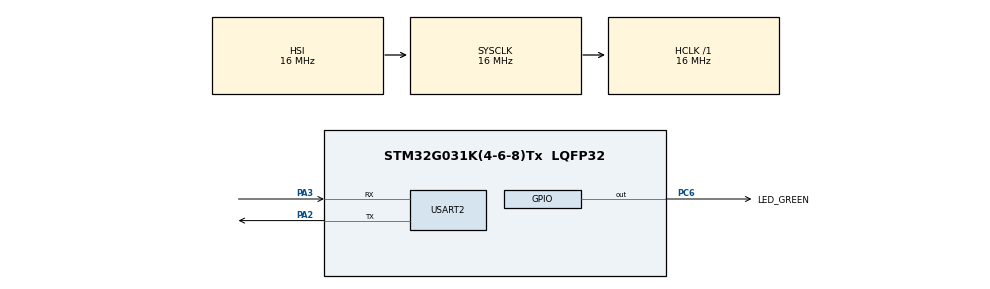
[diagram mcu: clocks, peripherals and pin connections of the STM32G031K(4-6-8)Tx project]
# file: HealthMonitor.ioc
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ADC1.Channel-0\#ChannelRegularConversion=ADC_CHANNEL_TEMPSENSOR
ADC1.Channel-1\#ChannelRegularConversion=ADC_CHANNEL_VREFINT
ADC1.ContinuousConvMode=ENABLE
ADC1.DMAContinuousRequests=ENABLE
ADC1.NbrOfConversion=2
ADC1.NbrOfConversionFlag=1
ADC1.Rank-1\#ChannelRegularConversion=2
ADC1.SamplingTime-1\#ChannelRegularConversion=ADC_SAMPLINGTIME_COMMON_1
ADC1.SamplingTimeCommon1=ADC_SAMPLETIME_160CYCLES_5
ADC1.SelectedChannel=ADC_CHANNEL_TEMPSENSOR|ADC_CHANNEL_VREFINT
ADC1.master=1
Dma.ADC1.0.Direction=DMA_PERIPH_TO_MEMORY
Dma.ADC1.0.EventEnable=DISABLE
Dma.ADC1.0.Instance=DMA1_Channel1
Dma.ADC1.0.MemDataAlignment=DMA_MDATAALIGN_HALFWORD
Dma.ADC1.0.MemInc=DMA_MINC_ENABLE
Dma.ADC1.0.Mode=DMA_CIRCULAR
Dma.ADC1.0.PeriphDataAlignment=DMA_PDATAALIGN_HALFWORD
Dma.ADC1.0.PeriphInc=DMA_PINC_DISABLE
Dma.ADC1.0.Polarity=HAL_DMAMUX_REQ_GEN_RISING
Dma.ADC1.0.Priority=DMA_PRIORITY_LOW
Dma.ADC1.0.RequestNumber=1
Dma.ADC1.0.SignalID=NONE
Dma.ADC1.0.SyncEnable=DISABLE
Dma.ADC1.0.SyncPolarity=HAL_DMAMUX_SYNC_NO_EVENT
Dma.ADC1.0.SyncRequestNumber=1
Dma.ADC1.0.SyncSignalID=NONE
Dma.Request0=ADC1
Mcu.Family=STM32G0
Mcu.Name=STM32G031K(4-6-8)Tx
Mcu.Package=LQFP32
NVIC.DMA1_Channel1_IRQn=true\:0\:0\:false\:false\:true\:false\:true\:true
PA2.Mode=Asynchronous
PA2.Signal=USART2_TX
PA3.Mode=Asynchronous
PA3.Signal=USART2_RX
PC6.GPIO_Label=LED_GREEN
PC6.Signal=GPIO_Output
ProjectManager.HeapSize=0x200
ProjectManager.StackSize=0x400
ProjectManager.TargetToolchain=STM32CubeIDE
RCC.AHBFreq_Value=16000000
RCC.CortexFreq_Value=16000000
RCC.EXTERNAL_CLOCK_VALUE=12288000
RCC.HCLKFreq_Value=16000000
RCC.HSE_VALUE=8000000
RCC.HSI_VALUE=16000000
RCC.LSE_VALUE=32768
RCC.SYSCLKFreq_VALUE=16000000
RCC.VCOOutputFreq_Value=128000000
USART2.VirtualMode-Asynchronous=VM_ASYNC
VP_ADC1_TempSens_Input.Mode=IN-TempSens
VP_ADC1_Vref_Input.Mode=IN-Vrefint
board=NUCLEO-G031K8

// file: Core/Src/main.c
/* USER CODE BEGIN Header */
/**
 ******************************************************************************
 * @file           : main.c
 * @brief          : Main program body
 ******************************************************************************
 * @attention
 *
 * Copyright (c) 2026 STMicroelectronics.
 * All rights reserved.
 *
 * This software is licensed under terms that can be found in the LICENSE file
 * in the root directory of this software component.
 * If no LICENSE file comes with this software, it is provided AS-IS.
 *
 ******************************************************************************
 */
/* USER CODE END Header */
#include "main.h"

/* USER CODE BEGIN Includes */
#include <stdio.h>
#include <string.h>
/* USER CODE END Includes */

ADC_HandleTypeDef hadc1;
DMA_HandleTypeDef hdma_adc1;

UART_HandleTypeDef huart2;

/* USER CODE BEGIN PV */
// Buffer to hold raw data: [0]=Temp, [1]=Vref
uint16_t adc_buffer[2];
/* USER CODE END PV */

void SystemClock_Config(void);
static void MX_DMA_Init(void);
static void MX_GPIO_Init(void);
static void MX_ADC1_Init(void);
static void MX_USART2_UART_Init(void);

int main(void)
{

  /* MCU Configuration--------------------------------------------------------*/

  /* Reset of all peripherals, Initializes the Flash interface and the Systick. */
  HAL_Init();

  /* Configure the system clock */
  SystemClock_Config();

  /* Initialize all configured peripherals */
  MX_DMA_Init();
  MX_GPIO_Init();
  MX_ADC1_Init();
  MX_USART2_UART_Init();
  /* USER CODE BEGIN 2 */
	// Calibrate the ADC for better accuracy
	HAL_ADCEx_Calibration_Start(&hadc1);

	// Start the ADC in DMA mode
	// It will fill 'adc_buffer' and loop back to start automatically
	HAL_ADC_Start_DMA(&hadc1, (uint32_t*) adc_buffer, 2);
  /* USER CODE END 2 */

  /* Infinite loop */
  /* USER CODE BEGIN WHILE */
	char msg[64];

	// 1. Define the Factory Calibration Addresses (From Datasheet)
#define TS_CAL1_ADDR ((uint16_t*) ((uint32_t)0x1FFF75A8)) // Value at 30 degrees C
#define TS_CAL2_ADDR ((uint16_t*) ((uint32_t)0x1FFF75CA)) // Value at 130 degrees C
#ifndef VREFINT_CAL_ADDR
    #define VREFINT_CAL_ADDR   ((uint16_t*) ((uint32_t)0x1FFF75AA)) // 3.0V
#endif

	while (1) {
		// --- Step 1: Calculate Actual System Voltage (VDDA) ---
		// We use the Internal Reference (Vref) to find out the real supply voltage
		uint16_t vref_cal = *VREFINT_CAL_ADDR;
		uint16_t vref_data = adc_buffer[1];

		// Formula: VDDA = 3.0V * (VREF_CAL / VREF_DATA)
		// Result in millivolts (e.g., 3300 mV)
		uint32_t vdda_mv = (3000 * vref_cal) / vref_data;

		// --- Step 2: Calculate Temperature ---
		// We use the slope formula with the calibration points
		int32_t ts_cal1 = (int32_t) *TS_CAL1_ADDR;
		int32_t ts_cal2 = (int32_t) *TS_CAL2_ADDR;

		// Normalize the raw reading to 3.0V reference
		// (Raw * Actual_Voltage) / 3000mV
		int32_t ts_data_raw = (int32_t) adc_buffer[0];
		int32_t ts_data_corrected = (ts_data_raw * vdda_mv) / 3000;
		// Standard Linear Interpolation Formula for STM32
		int32_t temperature_c = ((110 * (ts_data_corrected - ts_cal1))
				/ (ts_cal2 - ts_cal1)) + 30;

		// --- Step 3: Print Results ---
		// CSV Format (Voltage,Temperature)
		sprintf(msg, "%lu,%ld\r\n", vdda_mv, temperature_c);
		//sprintf(msg, "Volt: %lu mV | Temp: %ld C\r\n", vdda_mv, temperature_c);
		HAL_UART_Transmit(&huart2, (uint8_t*) msg, strlen(msg), 100);

		HAL_Delay(1000);

		// --- Step 4: System Protection (The "Thermostat") ---
		// If we touch the chip and it warms up, trigger the alarm.
		if (temperature_c > 31) {
			// HOT! Turn on LED (PC6 for Nucleo-G031K8)
			HAL_GPIO_WritePin(GPIOC, GPIO_PIN_6, GPIO_PIN_SET);
			strcat(msg, " [ALARM: OVERHEATING]"); // Append warning to UART log
		} else {
			// Cool. Turn off LED.
			HAL_GPIO_WritePin(GPIOC, GPIO_PIN_6, GPIO_PIN_RESET);
		}

    /* USER CODE END WHILE */

	}
}

void SystemClock_Config(void)
{
  RCC_OscInitTypeDef RCC_OscInitStruct = {0};
  RCC_ClkInitTypeDef RCC_ClkInitStruct = {0};

  /** Configure the main internal regulator output voltage
  */
  HAL_PWREx_ControlVoltageScaling(PWR_REGULATOR_VOLTAGE_SCALE1);

  /** Initializes the RCC Oscillators according to the specified parameters
  * in the RCC_OscInitTypeDef structure.
  */
  RCC_OscInitStruct.OscillatorType = RCC_OSCILLATORTYPE_HSI;
  RCC_OscInitStruct.HSIState = RCC_HSI_ON;
  RCC_OscInitStruct.HSIDiv = RCC_HSI_DIV1;
  RCC_OscInitStruct.HSICalibrationValue = RCC_HSICALIBRATION_DEFAULT;
  RCC_OscInitStruct.PLL.PLLState = RCC_PLL_NONE;
  if (HAL_RCC_OscConfig(&RCC_OscInitStruct) != HAL_OK)
  {
    Error_Handler();
  }

  /** Initializes the CPU, AHB and APB buses clocks
  */
  RCC_ClkInitStruct.ClockType = RCC_CLOCKTYPE_HCLK|RCC_CLOCKTYPE_SYSCLK
                              |RCC_CLOCKTYPE_PCLK1;
  RCC_ClkInitStruct.SYSCLKSource = RCC_SYSCLKSOURCE_HSI;
  RCC_ClkInitStruct.AHBCLKDivider = RCC_SYSCLK_DIV1;
  RCC_ClkInitStruct.APB1CLKDivider = RCC_HCLK_DIV1;

  if (HAL_RCC_ClockConfig(&RCC_ClkInitStruct, FLASH_LATENCY_0) != HAL_OK)
  {
    Error_Handler();
  }
}

static void MX_ADC1_Init(void)
{

  ADC_ChannelConfTypeDef sConfig = {0};

  /** Configure the global features of the ADC (Clock, Resolution, Data Alignment and number of conversion)
  */
  hadc1.Instance = ADC1;
  hadc1.Init.ClockPrescaler = ADC_CLOCK_SYNC_PCLK_DIV2;
  hadc1.Init.Resolution = ADC_RESOLUTION_12B;
  hadc1.Init.DataAlign = ADC_DATAALIGN_RIGHT;
  hadc1.Init.ScanConvMode = ADC_SCAN_ENABLE;
  hadc1.Init.EOCSelection = ADC_EOC_SINGLE_CONV;
  hadc1.Init.LowPowerAutoWait = DISABLE;
  hadc1.Init.LowPowerAutoPowerOff = DISABLE;
  hadc1.Init.ContinuousConvMode = ENABLE;
  hadc1.Init.NbrOfConversion = 2;
  hadc1.Init.ExternalTrigConv = ADC_SOFTWARE_START;
  hadc1.Init.ExternalTrigConvEdge = ADC_EXTERNALTRIGCONVEDGE_NONE;
  hadc1.Init.DMAContinuousRequests = ENABLE;
  hadc1.Init.Overrun = ADC_OVR_DATA_PRESERVED;
  hadc1.Init.SamplingTimeCommon1 = ADC_SAMPLETIME_160CYCLES_5;
  hadc1.Init.SamplingTimeCommon2 = ADC_SAMPLETIME_1CYCLE_5;
  hadc1.Init.OversamplingMode = DISABLE;
  hadc1.Init.TriggerFrequencyMode = ADC_TRIGGER_FREQ_HIGH;
  if (HAL_ADC_Init(&hadc1) != HAL_OK)
  {
    Error_Handler();
  }

  /** Configure Regular Channel
  */
  sConfig.Channel = ADC_CHANNEL_TEMPSENSOR;
  sConfig.Rank = ADC_REGULAR_RANK_1;
  sConfig.SamplingTime = ADC_SAMPLINGTIME_COMMON_1;
  if (HAL_ADC_ConfigChannel(&hadc1, &sConfig) != HAL_OK)
  {
    Error_Handler();
  }

  /** Configure Regular Channel
  */
  sConfig.Channel = ADC_CHANNEL_VREFINT;
  sConfig.Rank = ADC_REGULAR_RANK_2;
  if (HAL_ADC_ConfigChannel(&hadc1, &sConfig) != HAL_OK)
  {
    Error_Handler();
  }

}

static void MX_USART2_UART_Init(void)
{

  huart2.Instance = USART2;
  huart2.Init.BaudRate = 115200;
  huart2.Init.WordLength = UART_WORDLENGTH_8B;
  huart2.Init.StopBits = UART_STOPBITS_1;
  huart2.Init.Parity = UART_PARITY_NONE;
  huart2.Init.Mode = UART_MODE_TX_RX;
  huart2.Init.HwFlowCtl = UART_HWCONTROL_NONE;
  huart2.Init.OverSampling = UART_OVERSAMPLING_16;
  huart2.Init.OneBitSampling = UART_ONE_BIT_SAMPLE_DISABLE;
  huart2.Init.ClockPrescaler = UART_PRESCALER_DIV1;
  huart2.AdvancedInit.AdvFeatureInit = UART_ADVFEATURE_NO_INIT;
  if (HAL_UART_Init(&huart2) != HAL_OK)
  {
    Error_Handler();
  }

}

static void MX_DMA_Init(void)
{

  /* DMA controller clock enable */
  __HAL_RCC_DMA1_CLK_ENABLE();

  /* DMA interrupt init */
  /* DMA1_Channel1_IRQn interrupt configuration */
  HAL_NVIC_SetPriority(DMA1_Channel1_IRQn, 0, 0);
  HAL_NVIC_EnableIRQ(DMA1_Channel1_IRQn);

}

static void MX_GPIO_Init(void)
{
  GPIO_InitTypeDef GPIO_InitStruct = {0};

  /* GPIO Ports Clock Enable */
  __HAL_RCC_GPIOA_CLK_ENABLE();
  __HAL_RCC_GPIOC_CLK_ENABLE();

  /*Configure GPIO pin Output Level */
  HAL_GPIO_WritePin(LED_GREEN_GPIO_Port, LED_GREEN_Pin, GPIO_PIN_RESET);

  /*Configure GPIO pin : LED_GREEN_Pin */
  GPIO_InitStruct.Pin = LED_GREEN_Pin;
  GPIO_InitStruct.Mode = GPIO_MODE_OUTPUT_PP;
  GPIO_InitStruct.Pull = GPIO_NOPULL;
  GPIO_InitStruct.Speed = GPIO_SPEED_FREQ_LOW;
  HAL_GPIO_Init(LED_GREEN_GPIO_Port, &GPIO_InitStruct);

}

void Error_Handler(void)
{
	__disable_irq();
	while (1) {
	}
}
